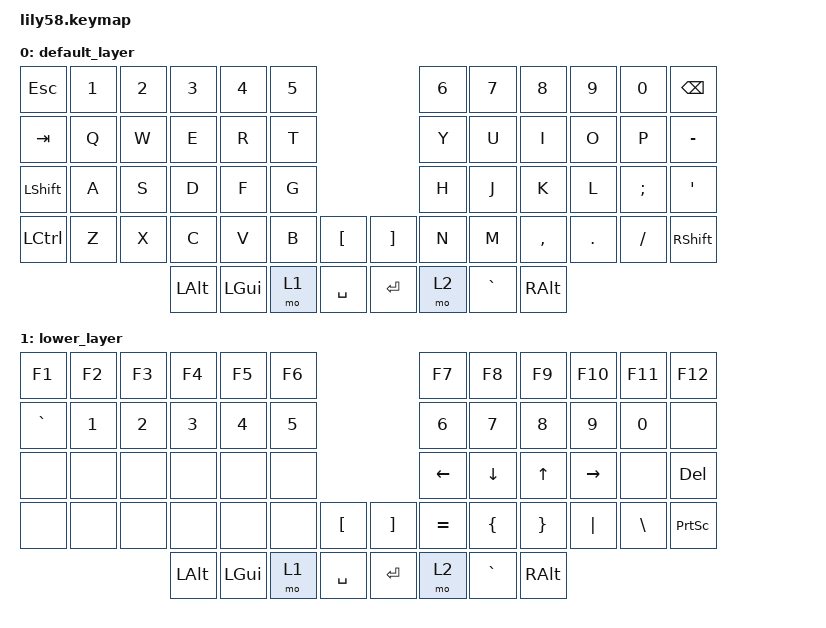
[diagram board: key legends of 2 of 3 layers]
/*
 * Copyright (c) 2020 The ZMK Contributors
 *
 * SPDX-License-Identifier: MIT
 */

#include <behaviors.dtsi>
#include <dt-bindings/zmk/keys.h>
#include <dt-bindings/zmk/bt.h>
#include <dt-bindings/zmk/ext_power.h>
#include <dt-bindings/zmk/rgb.h>

/ {
    // Activar la capa ADJUST presionando raise y lower
    conditional_layers {
        compatible = "zmk,conditional-layers";
    };

    keymap {
        compatible = "zmk,keymap";

        default_layer {
            /* default_layer
             * ,-----------------------------------------.                    ,-----------------------------------------.
             * | ESC  |   1  |   2  |   3  |   4  |   5  |                    |   6  |   7  |   8  |   9  |   0  |BackSP|
             * |------+------+------+------+------+------|                    |------+------+------+------+------+------|
             * | Tab  |   Q  |   W  |   E  |   R  |   T  |                    |   Y  |   U  |   I  |   O  |   P  |  -   |
             * |------+------+------+------+------+------|                    |------+------+------+------+------+------|
             * |LShift|   A  |   S  |   D  |   F  |   G  |-------.    ,-------|   H  |   J  |   K  |   L  |   ;  |  '   |
             * |------+------+------+------+------+------|   [   |    |    ]  |------+------+------+------+------+------|
             * |LCTRL |   Z  |   X  |   C  |   V  |   B  |-------|    |-------|   N  |   M  |   ,  |   .  |   /  |RShift|
             * `-----------------------------------------/       /     \      \-----------------------------------------'
             *                   | LAlt | LGUI |LOWER | /Space  /       \Enter \  |RAISE |  `   | RALT |
             *                   |      |      |      |/       /         \      \ |      |      |      |
             *                   `----------------------------'           '------''--------------------'
             */
            bindings = <
                &kp ESC   &kp N1 &kp N2 &kp N3   &kp N4   &kp N5                     &kp N6 &kp N7   &kp N8    &kp N9  &kp N0   &kp BSPC
                &kp TAB   &kp Q  &kp W  &kp E    &kp R    &kp T                      &kp Y  &kp U    &kp I     &kp O   &kp P    &kp MINUS
                &kp LSHFT &kp A  &kp S  &kp D    &kp F    &kp G                      &kp H  &kp J    &kp K     &kp L   &kp SEMI &kp SQT
                &kp LCTRL &kp Z  &kp X  &kp C    &kp V    &kp B  &kp LBKT    &kp RBKT &kp N  &kp M    &kp COMMA &kp DOT &kp FSLH &kp RSHFT
                                        &kp LALT &kp LGUI &mo 1  &kp SPACE   &kp RET  &mo 2  &kp GRAVE &kp RALT
            >;

            sensor-bindings = <&inc_dec_kp C_VOL_UP C_VOL_DN &inc_dec_kp DOWN UP>;
        };

        lower_layer {
            /* LOWER
             * ,-----------------------------------------.                    ,-----------------------------------------.
             * |  F1  |  F2  |  F3  |  F4  |  F5  |  F6  |                    |  F7  |  F8  |  F9  | F10  | F11  | F12  |
             * |------+------+------+------+------+------|                    |------+------+------+------+------+------|
             * |   `  |   1  |   2  |   3  |   4  |   5  |                    |   6  |   7  |   8  |   9  |   0  |      |
             * |------+------+------+------+------+------|                    |------+------+------+------+------+------|
             * |      |      |      |      |      |      |-------.    ,-------| Left | Down |  Up  | Right|      | Del  |
             * |------+------+------+------+------+------|   [   |    |    ]  |------+------+------+------+------+------|
             * |      |      |      |      |      |      |-------|    |-------|   =  |   [  |   ]  |   \  |   |  | PrSc |
             * `-----------------------------------------/       /     \      \-----------------------------------------'
             *                   | LAlt | LGUI |LOWER | /Space  /       \Enter \  |RAISE | `    | RALT |
             *                   |      |      |      |/       /         \      \ |      |      |      |
             *                   `----------------------------'           '------''--------------------'
             */
            bindings = <
                &kp F1    &kp F2    &kp F3    &kp F4    &kp F5    &kp F6                        &kp F7    &kp F8    &kp F9    &kp F10   &kp F11   &kp F12
                &kp GRAVE &kp N1    &kp N2    &kp N3    &kp N4    &kp N5                        &kp N6    &kp N7    &kp N8    &kp N9    &kp N0    &none
                &none     &none     &none     &none     &none     &none                         &kp LEFT  &kp DOWN  &kp UP    &kp RIGHT &none     &kp DEL
                &none     &none     &none     &none     &none     &none  &kp LBKT    &kp RBKT   &kp EQUAL &kp LBRC  &kp RBRC  &kp PIPE &kp BSLH   &kp PRINTSCREEN
                                              &kp LALT  &kp LGUI  &mo 1  &kp SPACE  &kp RET     &mo 2     &kp GRAVE &kp RALT
            >;

            sensor-bindings = <&inc_dec_kp C_VOL_UP C_VOL_DN &inc_dec_kp LEFT RIGHT>;
        };

        raise_layer {
            /* RAISE
             * ,-----------------------------------------.                    ,-----------------------------------------.
             * |      | BT1  | BT2  | BT3  | BT4  | BT5  |                    |      |      |      |      |      |      |
             * |------+------+------+------+------+------|                    |------+------+------+------+------+------|
             * |RGB_TOG|RGBHUD|RGBHUI|RGBSAD|RGBSAI|RGBEFF|                   |      |      |      |      |      |      |
             * |------+------+------+------+------+------|                    |------+------+------+------+------+------|
             * |      |RGBBRD|RGBBRI|      |      |      |-------.    ,-------| Left | Down |  Up  | Right|      |
             * |------+------+------+------+------+------|       |    |       |------+------+------+------+------+------|
             * | BTCLR|      |      |      |      |      |-------|    |-------|      |      |      |      |      |      |
             * `-----------------------------------------/       /     \      \-----------------------------------------'
             *                   | LAlt | LGUI |LOWER | /Space  /       \Enter \  |RAISE | `    | RALT |
             *                   |      |      |      |/       /         \      \ |      |      |      |
             *                   `----------------------------'           '------''--------------------'
             */
            bindings = <
                &none       &bt BT_SEL 0    &bt BT_SEL 1    &bt BT_SEL 2    &bt BT_SEL 3    &bt BT_SEL 4                            &trans &trans &trans &trans &trans &trans
                &rgb_ug RGB_TOG &rgb_ug RGB_HUD &rgb_ug RGB_HUI &rgb_ug RGB_SAD &rgb_ug RGB_SAI &rgb_ug RGB_EFF                         &trans &trans &trans &trans &trans &trans
                &trans             &rgb_ug RGB_BRD &rgb_ug RGB_BRI &trans           &trans           &trans                                   &kp LEFT  &kp DOWN  &kp UP    &kp RIGHT &trans &trans
                &bt BT_CLR             &trans           &trans           &trans           &trans           &trans            &trans &trans  &trans &trans &trans &trans &trans &trans
                &trans           &trans           &trans           &trans            &trans           &trans  &trans &trans &trans &trans
            >;

            sensor-bindings = <&inc_dec_kp C_VOL_UP C_VOL_DN &inc_dec_kp DOWN UP>;
        };
     };
 };
